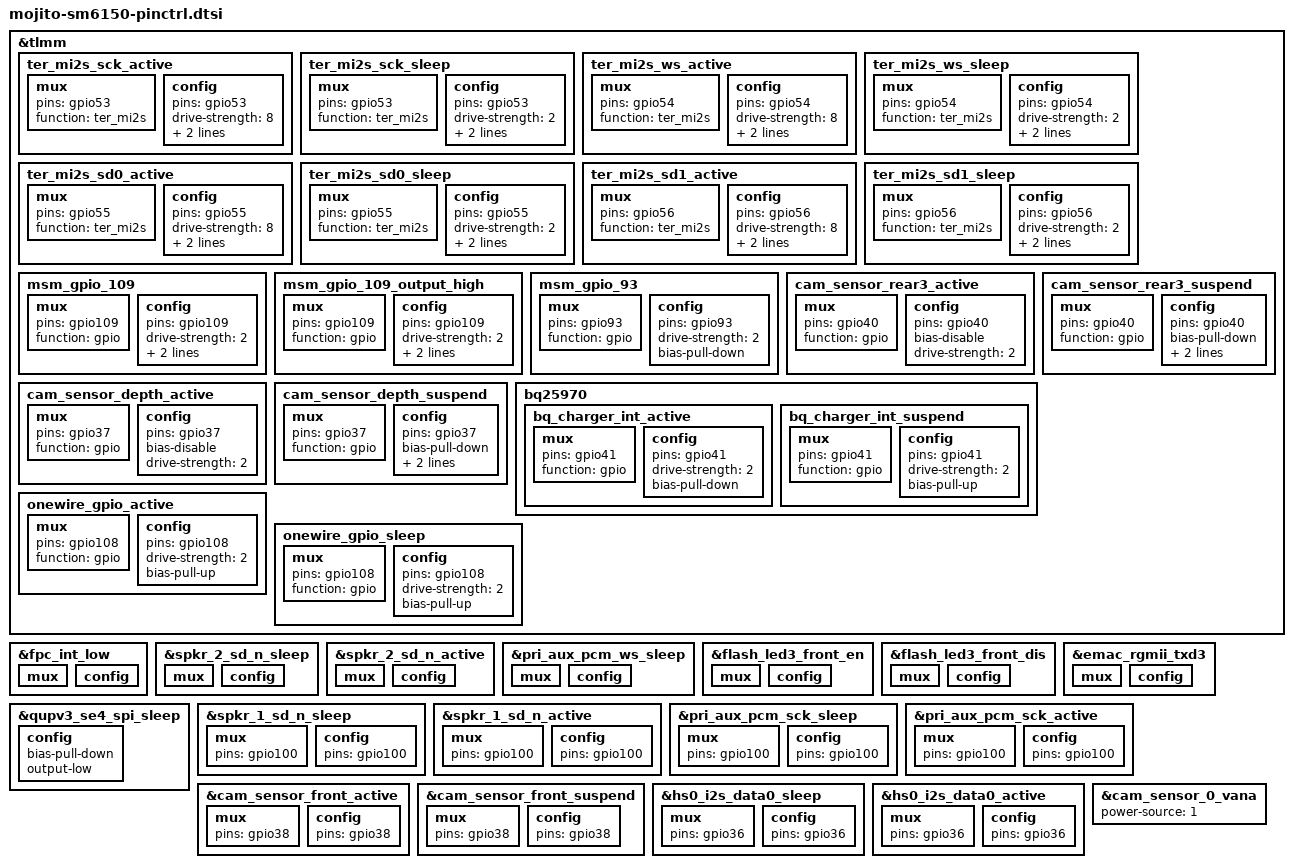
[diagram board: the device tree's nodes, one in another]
/*
 * Copyright (c) 2019, The Linux Foundation. All rights reserved.
 * Copyright (C) 2021 XiaoMi, Inc.
 *
 * This program is free software; you can redistribute it and/or modify
 * it under the terms of the GNU General Public License version 2 and
 * only version 2 as published by the Free Software Foundation.
 *
 * This program is distributed in the hope that it will be useful,
 * but WITHOUT ANY WARRANTY; without even the implied warranty of
 * MERCHANTABILITY or FITNESS FOR A PARTICULAR PURPOSE.  See the
 * GNU General Public License for more details.
 */

&tlmm {
	ter_mi2s_sck_active: ter_mi2s_sck_active {
		mux {
			pins = "gpio53";
			function = "ter_mi2s";
		};

		config {
			pins = "gpio53";
			drive-strength = <8>;
			bias-disable;
			output-high;
		};
	};

	ter_mi2s_sck_sleep: ter_mi2s_sck_sleep {
		mux {
			pins = "gpio53";
			function = "ter_mi2s";
		};

		config {
			pins = "gpio53";
			drive-strength = <2>;   /* 2 mA */
			bias-pull-down;         /* PULL DOWN */
			input-enable;
		};
	};

	ter_mi2s_ws_active: ter_mi2s_ws_active {
		mux {
			pins = "gpio54";
			function = "ter_mi2s";
		};

		config {
			pins = "gpio54";
			drive-strength = <8>;
			bias-disable;           /* NO PULL */
			output-high;
		};
	};

	ter_mi2s_ws_sleep: ter_mi2s_ws_sleep {
		mux {
			pins = "gpio54";
			function = "ter_mi2s";
		};

		config {
			pins = "gpio54";
			drive-strength = <2>;
			bias-pull-down;         /* PULL DOWN */
			input-enable;
		};
	};

	ter_mi2s_sd0_active: ter_mi2s_sd0_active {
		mux {
			pins = "gpio55";
			function = "ter_mi2s";
		};

		config {
			pins = "gpio55";
			drive-strength = <8>;
			bias-disable;           /* NO PULL */
			output-high;
		};
	};

	ter_mi2s_sd0_sleep: ter_mi2s_sd0_sleep {
		mux {
			pins = "gpio55";
			function = "ter_mi2s";
		};

		config {
			pins = "gpio55";
			drive-strength = <2>;
			bias-pull-down;         /* PULL DOWN */
			input-enable;
		};
	};

	ter_mi2s_sd1_active: ter_mi2s_sd1_active {
		mux {
			pins = "gpio56";
			function = "ter_mi2s";
		};

		config {
			pins = "gpio56";
			drive-strength = <8>;
			bias-disable;           /* NO PULL */
			output-high;
		};
	};

	ter_mi2s_sd1_sleep: ter_mi2s_sd1_sleep {
		mux {
			pins = "gpio56";
			function = "ter_mi2s";
		};

		config {
			pins = "gpio56";
			drive-strength = <2>;
			bias-pull-down;         /* PULL DOWN */
			input-enable;
		};
	};

	/* GPIO_109 : FP_RESET_N */
	msm_gpio_109: msm_gpio_109 {
		mux {
			pins = "gpio109";
			function = "gpio";
		};

		config {
			pins = "gpio109";
			drive-strength = <2>;
			bias-disable;
			output-low;
		};
	};

	/* GPIO_109 : FP_RESET_N, state device active */
	msm_gpio_109_output_high: msm_gpio_109_output_high {
		mux {
			pins = "gpio109";
			function = "gpio";
		};

		config {
			pins = "gpio109";
			drive-strength = <2>;
			bias-disable;
			output-high;
		};
	};

	/* GPIO_93 : FP_INT_N */
	msm_gpio_93: msm_gpio_93 {
		mux {
			pins = "gpio93";
			function = "gpio";
		};

		config {
			pins = "gpio93";
			drive-strength = <2>;
			bias-pull-down;
		};
	};

	cam_sensor_rear3_active: cam_sensor_rear3_active {
		/* RESET */
		mux {
			pins = "gpio40";
			function = "gpio";
		};

		config {
			pins = "gpio40";
			bias-disable; /* No PULL */
			drive-strength = <2>; /* 2 MA */
		};
	};

	cam_sensor_rear3_suspend: cam_sensor_rear3_suspend {
		/* RESET */
		mux {
			pins = "gpio40";
			function = "gpio";
		};

		config {
			pins = "gpio40";
			bias-pull-down; /* PULL DOWN */
			drive-strength = <2>; /* 2 MA */
			output-low;
		};
	};

	cam_sensor_depth_active: cam_sensor_depth_active {
		/* RESET */
		mux {
			pins = "gpio37";
			function = "gpio";
		};

		config {
			pins = "gpio37";
			bias-disable; /* No PULL */
			drive-strength = <2>; /* 2 MA */
		};
	};

	cam_sensor_depth_suspend: cam_sensor_depth_suspend {
		/* RESET */
		mux {
			pins = "gpio37";
			function = "gpio";
		};

		config {
			pins = "gpio37";
			bias-pull-down; /* PULL DOWN */
			drive-strength = <2>; /* 2 MA */
			output-low;
		};
	};

	bq25970 {
		bq_charger_int_active: bq_charger_int_active {
			mux {
				pins = "gpio41";
				function = "gpio";
			};

			config {
				pins = "gpio41";
				drive-strength = <2>;
				bias-pull-down;
			};
		};

		bq_charger_int_suspend: bq_charger_int_suspend {
			mux {
				pins = "gpio41";
				function = "gpio";
			};

			config {
				pins = "gpio41";
				drive-strength = <2>;
				bias-pull-up;
			};
		};
	};

	onewire_gpio_active: onewire_gpio_active {
		mux {
			pins = "gpio108";
			function = "gpio";
		};

		config {
			pins = "gpio108";
			drive-strength = <2>;
			bias-pull-up;
		};
	};

	onewire_gpio_sleep: onewire_gpio_sleep {
		mux {
			pins = "gpio108";
			function = "gpio";
		};

		config {
			pins = "gpio108";
			drive-strength = <2>;
			bias-pull-up;
		};
	};
};

&fpc_int_low {
	mux {
		/delete-property/ pins;
	};

	config {
		/delete-property/ pins;
	};
};

&spkr_2_sd_n_sleep {
	mux {
		/delete-property/ pins;
	};

	config {
		/delete-property/ pins;
	};
};

&spkr_2_sd_n_active {
	mux {
		/delete-property/ pins;
	};

	config {
		/delete-property/ pins;
	};
};

&pri_aux_pcm_ws_sleep {
	mux {
		/delete-property/ pins;
	};

	config {
		/delete-property/ pins;
	};
};

&flash_led3_front_en {
	mux {
		/delete-property/ pins;
	};

	config {
		/delete-property/ pins;
	};
};

&flash_led3_front_dis {
	mux {
		/delete-property/ pins;
	};

	config {
		/delete-property/ pins;
	};
};

&emac_rgmii_txd3 {
	mux {
		/delete-property/ pins;  
	};

	config {
		/delete-property/ pins;
	};
};

&qupv3_se4_spi_sleep {
	config {
		/delete-property/ bias-disable;

		bias-pull-down;
		output-low;
	};
};

&spkr_1_sd_n_sleep {
	mux {
		pins = "gpio100";
	};

	config {
		pins = "gpio100";
	};
};

&spkr_1_sd_n_active {
	mux {
		pins = "gpio100";
	};

	config {
		pins = "gpio100";
	};
};

&pri_aux_pcm_sck_sleep {
	mux {
		pins = "gpio100";
	};

	config {
		pins = "gpio100";
	};
};

&pri_aux_pcm_sck_active {
	mux {
		pins = "gpio100";
	};

	config {
		pins = "gpio100";
	};
};

&cam_sensor_front_active {
	mux {
		pins = "gpio38";
	};

	config {
		pins = "gpio38";
	};
};

&cam_sensor_front_suspend {
	mux {
		pins = "gpio38";
	};

	config {
		pins = "gpio38";
	};
};

&hs0_i2s_data0_sleep {
	mux {
		pins = "gpio36";
	};

	config {
		pins = "gpio36";
	};
};

&hs0_i2s_data0_active {
	mux {
		pins = "gpio36";
	};

	config {
		pins = "gpio36";
	};
};

&cam_sensor_0_vana {
	power-source = <1>;
};
